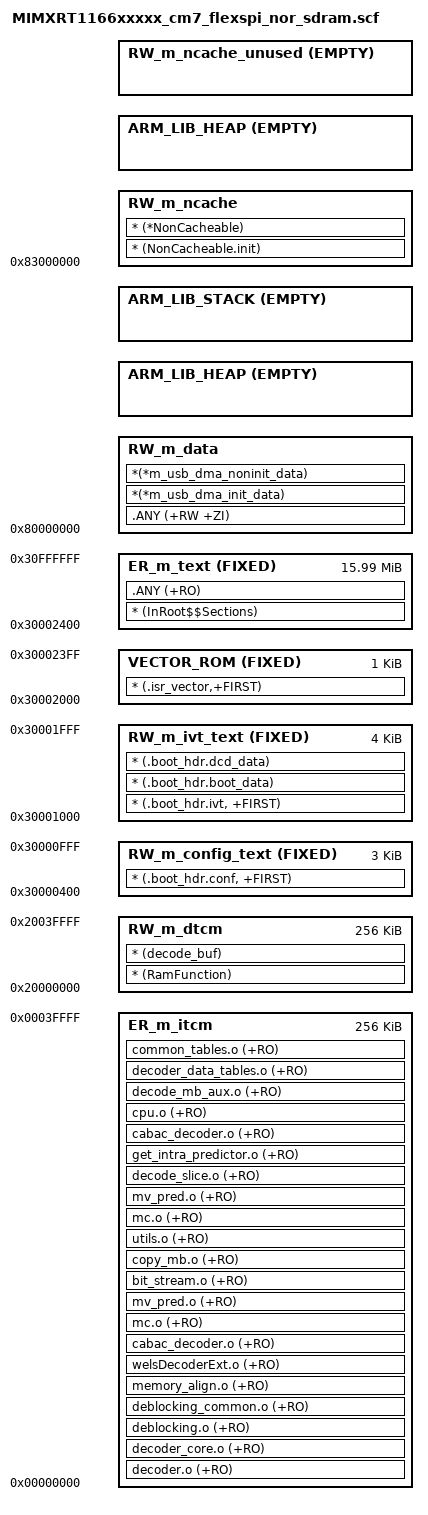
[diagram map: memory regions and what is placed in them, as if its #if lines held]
#!armclang --target=arm-arm-none-eabi -mcpu=cortex-m7 -E -x c
/*
** ###################################################################
**     Processors:          MIMXRT1166CVM5A_cm7
**                          MIMXRT1166DVM6A_cm7
**
**     Compiler:            Keil ARM C/C++ Compiler
**     Reference manual:    IMXRT1160RM, Rev B, 02/2021
**     Version:             rev. 0.1, 2020-12-29
**     Build:               b210226
**
**     Abstract:
**         Linker file for the Keil ARM C/C++ Compiler
**
**     Copyright 2016 Freescale Semiconductor, Inc.
**     Copyright 2016-2021 NXP
**     All rights reserved.
**
**     SPDX-License-Identifier: BSD-3-Clause
**
**     http:                 www.nxp.com
**     mail:                 support@nxp.com
**
** ###################################################################
*/

#define m_flash_config_start           0x30000400
#define m_flash_config_size            0x00000C00

#define m_ivt_start                    0x30001000
#define m_ivt_size                     0x00001000

#define m_interrupts_start             0x30002000
#define m_interrupts_size              0x00000400

#define m_text_start                   0x30002400
#define m_text_size                    0x00FFDC00

#define m_itcm_start                   0x00000000
#define m_itcm_size                    0x00040000

#define m_dtcm_start                   0x20000000
#define m_dtcm_size                    0x00040000

#define m_ocram_start                  0x202C0000
#define m_ocram_size                   0x00010000

#define m_data_start                   0x80000000
#define m_data_size                    0x03000000

#define m_ncache_start                 0x83000000
#define m_ncache_size                  0x01000000



/* Sizes */
#if (defined(__stack_size__))
  #define Stack_Size                   __stack_size__
#else
  #define Stack_Size                   0x0400
#endif

#if (defined(__heap_size__))
  #define Heap_Size                    __heap_size__
#else
  #define Heap_Size                    0x0400
#endif

#if defined(XIP_BOOT_HEADER_ENABLE) && (XIP_BOOT_HEADER_ENABLE == 1)
LR_m_text m_flash_config_start m_text_start+m_text_size-m_flash_config_start {   ; load region size_region
  RW_m_config_text m_flash_config_start FIXED m_flash_config_size { ; load address = execution address
    * (.boot_hdr.conf, +FIRST)
  }

  RW_m_ivt_text m_ivt_start FIXED m_ivt_size { ; load address = execution address
    * (.boot_hdr.ivt, +FIRST)
    * (.boot_hdr.boot_data)
    * (.boot_hdr.dcd_data)
  }
#else
LR_m_text m_interrupts_start m_text_start+m_text_size-m_interrupts_start {   ; load region size_region
#endif
  VECTOR_ROM m_interrupts_start FIXED m_interrupts_size { ; load address = execution address
    * (.isr_vector,+FIRST)
  }
  ER_m_text m_text_start FIXED m_text_size { ; load address = execution address
    * (InRoot$$Sections)
    .ANY (+RO)
  }

  ER_m_itcm m_itcm_start m_itcm_size {
    decoder.o (+RO)
    decoder_core.o (+RO)
    deblocking.o (+RO)
    deblocking_common.o (+RO)
    memory_align.o (+RO)
    welsDecoderExt.o (+RO)
    cabac_decoder.o (+RO)
    mc.o (+RO)
    mv_pred.o (+RO)
    bit_stream.o (+RO)
    copy_mb.o (+RO)
    utils.o (+RO)
    mc.o (+RO)
    mv_pred.o (+RO)
    decode_slice.o (+RO)
    get_intra_predictor.o (+RO)
    cabac_decoder.o (+RO)
    cpu.o (+RO)
    decode_mb_aux.o (+RO)
    decoder_data_tables.o (+RO)
    common_tables.o (+RO)
  }

  RW_m_dtcm m_dtcm_start m_dtcm_size {
    * (RamFunction)
    * (decode_buf)
  }

#if (defined(__heap_noncacheable__))
  RW_m_data m_data_start m_data_size-Stack_Size { ; RW data
#else
  RW_m_data m_data_start m_data_size-Stack_Size-Heap_Size { ; RW data
#endif
    .ANY (+RW +ZI)
    *(*m_usb_dma_init_data)
    *(*m_usb_dma_noninit_data)
  }
#if (!defined(__heap_noncacheable__))
  ARM_LIB_HEAP +0 EMPTY Heap_Size {    ; Heap region growing up
  }
#endif
  ARM_LIB_STACK m_data_start+m_data_size EMPTY -Stack_Size { ; Stack region growing down
  }
#if (defined(__heap_noncacheable__))
  RW_m_ncache m_ncache_start m_ncache_size - Heap_Size { ; ncache RW data
#else
  RW_m_ncache m_ncache_start m_ncache_size { ; ncache RW data
#endif
    * (NonCacheable.init)
    * (*NonCacheable)
  }
#if (defined(__heap_noncacheable__))
  ARM_LIB_HEAP +0 EMPTY Heap_Size {    ; Heap region growing up
  }
  RW_m_ncache_unused +0 EMPTY m_ncache_size-ImageLength(RW_m_ncache)-Heap_Size { ; Empty region added for MPU configuration
#else
  RW_m_ncache_unused +0 EMPTY m_ncache_size-ImageLength(RW_m_ncache) { ; Empty region added for MPU configuration
#endif
  }
}
